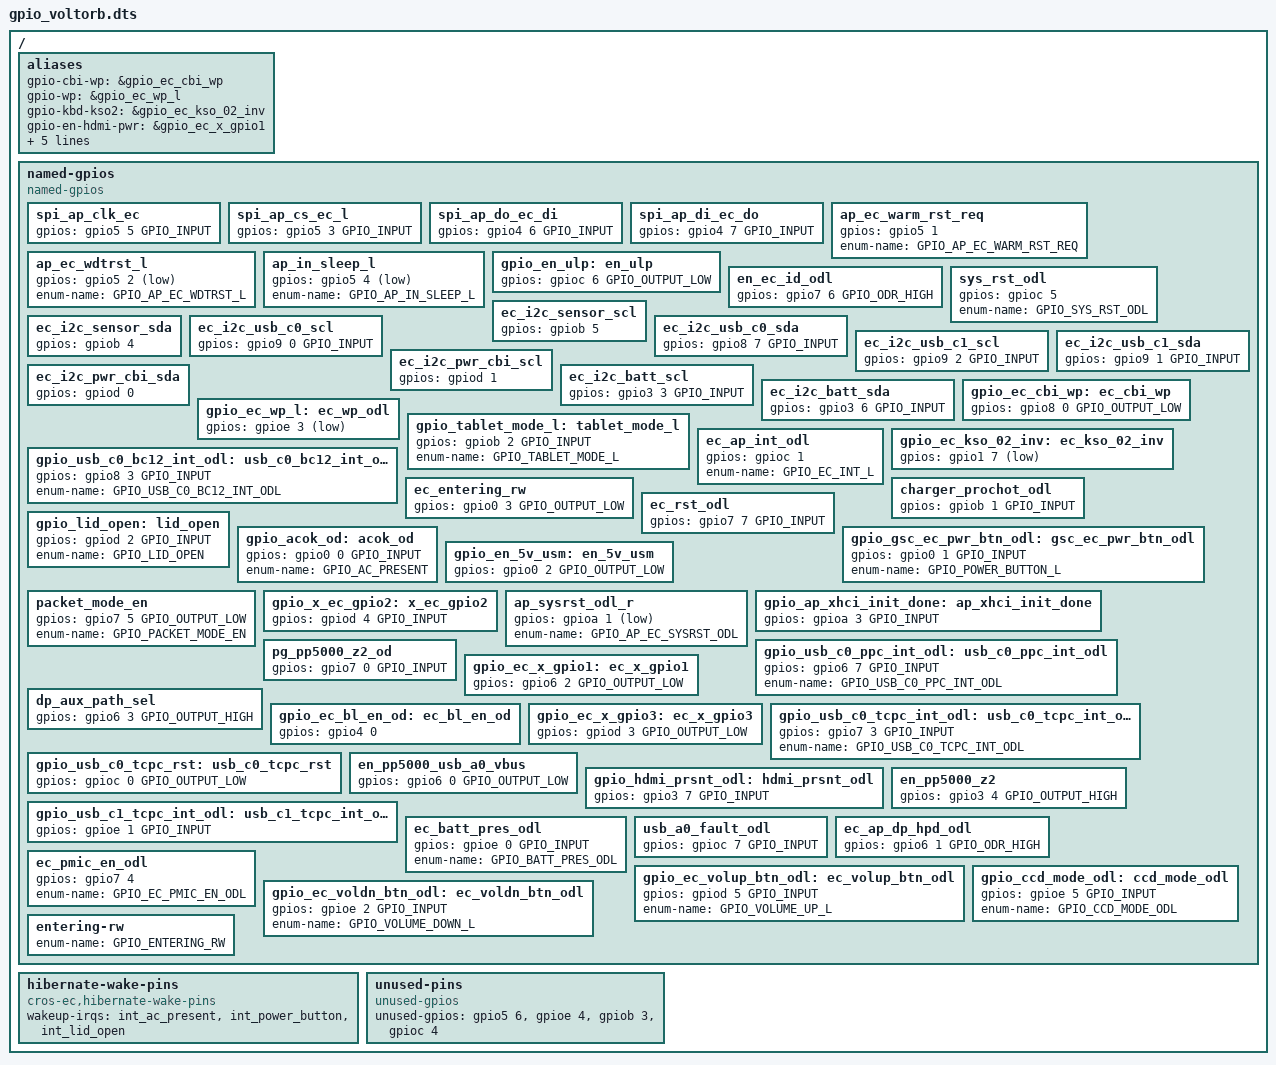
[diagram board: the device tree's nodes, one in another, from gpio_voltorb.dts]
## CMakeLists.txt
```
# Copyright 2021 The ChromiumOS Authors
# Use of this source code is governed by a BSD-style license that can be
# found in the LICENSE file.

cmake_minimum_required(VERSION 3.13.1)

find_package(Zephyr REQUIRED HINTS "${ZEPHYR_BASE}")

cros_ec_library_include_directories(include)

# Include selected EC source from the baseboard
zephyr_library_sources(
	"src/board.c"
	"src/hibernate.c"
)

zephyr_library_sources_ifdef(CONFIG_PLATFORM_EC_USBC "src/usbc.c")
zephyr_library_sources_ifdef(CONFIG_PLATFORM_EC_USBC "src/usb_pd_policy.c")
zephyr_library_sources_ifdef(CONFIG_VARIANT_CORSOLA_DB_DETECTION
			     "src/variant_db_detection.c")
zephyr_library_sources_ifndef(CONFIG_CORSOLA_BOARD_CHIPSET_CUSTOM "src/board_chipset.c")

if(DEFINED CONFIG_BOARD_KRABBY)
	project(krabby)
	add_subdirectory(krabby)
elseif(DEFINED CONFIG_BOARD_KINGLER)
	project(kingler)
	add_subdirectory(kingler)
elseif(DEFINED CONFIG_BOARD_KYOGRE)
	project(kyogre)
	add_subdirectory(kyogre)
elseif(DEFINED CONFIG_BOARD_STARMIE)
	project(starmie)
	add_subdirectory(starmie)
elseif(DEFINED CONFIG_BOARD_STEELIX)
	project(steelix)
	add_subdirectory(steelix)
elseif(DEFINED CONFIG_BOARD_TENTACRUEL)
	project(tentacruel)
	add_subdirectory(tentacruel)
elseif(DEFINED CONFIG_BOARD_MAGIKARP)
	project(magikarp)
	add_subdirectory(magikarp)
elseif(DEFINED CONFIG_BOARD_VOLTORB)
	project(voltorb)
	add_subdirectory(voltorb)
elseif(DEFINED CONFIG_BOARD_PONYTA)
	project(ponyta)
	add_subdirectory(ponyta)
elseif(DEFINED CONFIG_BOARD_CHINCHOU)
	project(chinchou)
	add_subdirectory(chinchou)
elseif(DEFINED CONFIG_BOARD_WUGTRIO)
	project(wugtrio)
	add_subdirectory(wugtrio)
elseif(DEFINED CONFIG_BOARD_SKITTY)
	project(skitty)
	add_subdirectory(skitty)
elseif(DEFINED CONFIG_BOARD_VELUZA)
	project(veluza)
	add_subdirectory(veluza)
elseif(DEFINED CONFIG_BOARD_SQUIRTLE)
	project(squirtle)
	add_subdirectory(squirtle)
elseif(DEFINED CONFIG_BOARD_WYRDEER)
	project(wyrdeer)
	add_subdirectory(wyrdeer)
elseif(DEFINED CONFIG_BOARD_MEWTWO)
    project(mewtwo)
    add_subdirectory(mewtwo)
endif()
```

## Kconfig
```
# Copyright 2021 The ChromiumOS Authors
# Use of this source code is governed by a BSD-style license that can be
# found in the LICENSE file.

config BOARD_KRABBY
	bool "Google Krabby Board"
	help
	  Build Google Krabby reference board. Krabby has MediaTek MT8186 SoC
	  with ITE it81202-bx EC.

config BOARD_KINGLER
	bool "Google Kingler Board"
	help
	  Build Google Kingler reference board. Krabby has MediaTek MT8186 SoC
	  with NPCX993FA0BX EC.

config BOARD_KYOGRE
	bool "Google Kyogre Board"
	help
	  Build Google Kyogre variant board. Kyogre is a variant of Kingler
	  and has MediaTek MT8186 SoC with NPCX993FA0BX EC.

config BOARD_STARMIE
	bool "Google Starmie Board"
	help
	  Build Google Starmie variant board. Starmie is a variant of Krabby
	  and has MediaTek MT8186 SoC with ITE it81202-bx EC

config BOARD_STEELIX
	bool "Google Steelix Board"
	help
	  Build Google Steelix variant board. Steelix is a variant of Kingler
	  and has MediaTek MT8186 SoC with NPCX993FA0BX EC.

config BOARD_TENTACRUEL
	bool "Google Tentacruel Board"
	help
	  Build Google Tentacruel variant board. Tentacruel is a variant of Krabby
	  and has MediaTek MT8186 SoC with ITE it81202-bx EC.

config BOARD_MAGIKARP
	bool "Google Magikarp Board"
	help
	  Build Google Magikarp variant board. Magikarp is a variant of Krabby
	  and has MediaTek MT8186 SoC with ITE it81202-bx EC.

config BOARD_VOLTORB
	bool "Google Voltorb Board"
	help
	  Build Google Voltorb variant board. Voltorb is a variant of Kingler
	  and has MediaTek MT8186/MT8186T SoC with NPCX993FA0BX EC.

config BOARD_PONYTA
	bool "Google Ponyta Board"
	help
	  Build Google Ponyta variant board. Ponyta is a variant of Kingler
	  and has MediaTek MT8186 SoC with NPCX993FA0BX EC.

config BOARD_CHINCHOU
	bool "Google Chinchou Board"
	help
	  Build Google Chinchou variant board. Chinchou is a variant of Krabby
	  and has MediaTek MT8186 SoC with ITE it81202-bx EC

config BOARD_WUGTRIO
	bool "Google Wugtrio Board"
	help
	  Build Google Wugtrio variant board. Wugtrio is a variant of Krabby
	  and has MediaTek MT8186 SoC with ITE it81202-bx EC

config BOARD_SKITTY
	bool "Google Skitty Board"
	help
	  Build Google Skitty variant board. Skitty is a variant of Krabby
	  and has MediaTek MT8186 SoC with ITE it81202-bx EC

config BOARD_VELUZA
	bool "Google Veluza Board"
	help
	  Build Google Veluza variant board. Veluza is a variant of Krabby
	  and has MediaTek MT8186 SoC with ITE it81202-bx EC

config BOARD_SQUIRTLE
	bool "Google Squirtle Board"
	help
	  Build Google Squirtle variant board. Squirtle is a variant of Kingler
	  and has MediaTek MT8186/MT8186T SoC with NPCX993FA0BX EC.

config BOARD_WYRDEER
	bool "Google Wyrdeer Board"
	help
	  Build Google Wyrdeer variant board. Wyrdeer is a variant of Krabby
	  and has MediaTek MT8186 SoC with ITE it81202-bx EC

config BOARD_MEWTWO
        bool "Google Squirtle Board"
        help
          Build Google Squirtle variant board. Squirtle is a variant of Kingler
          and has MediaTek MT8186/MT8186T SoC with NPCX993FA0BX EC.

config VARIANT_CORSOLA_DB_DETECTION
	bool "Corsola Platform Runtime Daughter Board Detection"
	depends on PLATFORM_EC_USB_PD_TCPC_RUNTIME_CONFIG
	depends on PLATFORM_EC_USB_MUX_RUNTIME_CONFIG
	help
	  Daughter board detection for Type-C subboard or HDMI subboard. This
          includes pin configuration and driver loading.
	default y

config CORSOLA_HIBERNATE_PRE_OFF_5V
	bool "Corsola Platform Hibernate Power Sequence Selection"
	help
	  Set PP5000_Z2 to deactivate before executing normal corsola hibernate.
	default n

config CORSOLA_BOARD_CHIPSET_CUSTOM
	bool "Corsola Platform Board Chipset Customization"
	help
	  Enable corsola platform customized AP power callbacks.
	default n

source "Kconfig.zephyr"
```

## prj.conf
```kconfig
# Copyright 2021 The ChromiumOS Authors
# Use of this source code is governed by a BSD-style license that can be
# found in the LICENSE file.
#

# http://google3/hardware/standards/usb/
CONFIG_PLATFORM_EC_USB_PID=0x505C

# CROS EC
CONFIG_CROS_EC=y
CONFIG_PLATFORM_EC=y
CONFIG_PLATFORM_EC_SWITCH=y
CONFIG_SHIMMED_TASKS=y

# AP SoC configuration
CONFIG_AP=y
CONFIG_AP_ARM_MTK_MT8186=y

# Variant config
CONFIG_VARIANT_CORSOLA_DB_DETECTION=y

# Shell features
CONFIG_KERNEL_SHELL=y
CONFIG_SHELL_HELP=y
CONFIG_SHELL_HISTORY=y
CONFIG_SHELL_TAB=y
CONFIG_SHELL_TAB_AUTOCOMPLETION=y

# CBI
CONFIG_EEPROM=y
CONFIG_PLATFORM_EC_BOARD_VERSION_CBI=y

# Keyboard
CONFIG_PLATFORM_EC_KEYBOARD=y
CONFIG_PLATFORM_EC_KEYBOARD_PROTOCOL_MKBP=y
CONFIG_PLATFORM_EC_KEYBOARD_COL2_INVERTED=y

# MKBP
CONFIG_PLATFORM_EC_MKBP_EVENT=y
CONFIG_PLATFORM_EC_MKBP_INPUT_DEVICES=y
CONFIG_PLATFORM_EC_MKBP_USE_GPIO=y

# EFS2
CONFIG_PLATFORM_EC_VBOOT_EFS2=y

# USB
CONFIG_PLATFORM_EC_USB_PD_TBT_COMPAT_MODE=n
CONFIG_PLATFORM_EC_USB_PD_USB32_DRD=n
CONFIG_PLATFORM_EC_USB_PD_USB4=n
CONFIG_PLATFORM_EC_USB_PORT_POWER_DUMB_CUSTOM_HOOK=y

# USB-C
CONFIG_PLATFORM_EC_USBC=y
CONFIG_PLATFORM_EC_USBC_SS_MUX_DFP_ONLY=y
CONFIG_PLATFORM_EC_USB_PD_DPS=y
CONFIG_PLATFORM_EC_USB_PD_DP_HPD_GPIO=y
CONFIG_PLATFORM_EC_USB_PD_DP_HPD_GPIO_CUSTOM=y
CONFIG_PLATFORM_EC_USB_PD_FRS=y
CONFIG_PLATFORM_EC_USB_PD_CLEAR_HARD_RESET_STATUS=y

# Power Seq
CONFIG_PLATFORM_EC_CHIPSET_RESUME_INIT_HOOK=y
CONFIG_PLATFORM_EC_EXTPOWER_GPIO=y
CONFIG_PLATFORM_EC_POWERSEQ=y
CONFIG_PLATFORM_EC_POWERSEQ_HOST_SLEEP=y
CONFIG_PLATFORM_EC_POWERSEQ_PP5000_CONTROL=n
CONFIG_PLATFORM_EC_POWER_SLEEP_FAILURE_DETECTION=y

# Optional features
CONFIG_FLASH_SHELL=n

# EEPROM
CONFIG_PLATFORM_EC_EEPROM_CBI_WP=y

# Host Commands
CONFIG_PLATFORM_EC_HOSTCMD=y

# Battery
CONFIG_PLATFORM_EC_BATTERY_CUT_OFF=y
CONFIG_PLATFORM_EC_BATTERY_FUEL_GAUGE=y
CONFIG_PLATFORM_EC_BATTERY_PRESENT_GPIO=y
CONFIG_PLATFORM_EC_BATTERY_SMART=y
CONFIG_PLATFORM_EC_BATT_FULL_CHIPSET_OFF_INPUT_LIMIT_MV=9000
CONFIG_PLATFORM_EC_I2C_PASSTHRU_RESTRICTED=y
CONFIG_PLATFORM_EC_I2C_VIRTUAL_BATTERY=y

# Charger
CONFIG_PLATFORM_EC_BC12_CLIENT_MODE_ONLY_PI3USB9201=y
CONFIG_PLATFORM_EC_CHARGE_MANAGER=y
# b:257167723: Adapter output current exceeds the spec on heavy-load.
# Preserve a margin in case of charger overdraw.
CONFIG_PLATFORM_EC_CHARGER_INPUT_CURRENT_DERATE_PCT=3

# Button
CONFIG_PLATFORM_EC_CMD_BUTTON=y
CONFIG_PLATFORM_EC_POWER_BUTTON=y
CONFIG_PLATFORM_EC_VOLUME_BUTTONS=y
```

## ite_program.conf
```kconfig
# Copyright 2022 The ChromiumOS Authors
# Use of this source code is governed by a BSD-style license that can be
# found in the LICENSE file.

# Bring up options
#CONFIG_SHELL_HISTORY_BUFFER=256
CONFIG_PLATFORM_EC_SYSTEM_UNLOCKED=y
CONFIG_PLATFORM_EC_BRINGUP=y

# Power Sequencing
CONFIG_PLATFORM_EC_CHIPSET_RESET_HOOK=y

# Lid Switch
CONFIG_PLATFORM_EC_LID_SWITCH=y

# Charger
CONFIG_PLATFORM_EC_CHARGE_RAMP_HW=y
CONFIG_PLATFORM_EC_CHARGER_DISCHARGE_ON_AC=y
CONFIG_PLATFORM_EC_CHARGER_DISCHARGE_ON_AC_CHARGER=y
CONFIG_PLATFORM_EC_CHARGER_MAINTAIN_VBAT=y
CONFIG_PLATFORM_EC_CHARGER_PSYS=y
CONFIG_PLATFORM_EC_CHARGER_PSYS_READ=y
# BOARD_RS2
CONFIG_PLATFORM_EC_CHARGER_SENSE_RESISTOR=10
# BOARD_RS1
CONFIG_PLATFORM_EC_CHARGER_SENSE_RESISTOR_AC=20
CONFIG_PLATFORM_EC_CONSOLE_CMD_CHARGER_DUMP=y

# Host Commands
CONFIG_PLATFORM_EC_CONSOLE_CMD_ACCELS=y
CONFIG_PLATFORM_EC_CONSOLE_CMD_ACCEL_INFO=y
CONFIG_PLATFORM_EC_CONSOLE_CMD_CHARGER_ADC_AMON_BMON=y
CONFIG_PLATFORM_EC_CONSOLE_CMD_SYSINFO=y
CONFIG_PLATFORM_EC_HOST_COMMAND_STATUS=y

# Sensors
CONFIG_PLATFORM_EC_ACCEL_FIFO=y
CONFIG_PLATFORM_EC_GMR_TABLET_MODE=y
CONFIG_PLATFORM_EC_LID_ANGLE=y
CONFIG_PLATFORM_EC_LID_ANGLE_UPDATE=y
CONFIG_PLATFORM_EC_SENSOR_TIGHT_TIMESTAMPS=y
CONFIG_PLATFORM_EC_TABLET_MODE=y
CONFIG_PLATFORM_EC_TABLET_MODE_SWITCH=y
CONFIG_PLATFORM_EC_MAX_SENSOR_FREQ_MILLIHZ=100000

# Sensor Drivers
CONFIG_PLATFORM_EC_ACCEL_LIS2DW12=y
CONFIG_PLATFORM_EC_ACCELGYRO_ICM42607=y
CONFIG_PLATFORM_EC_ACCELGYRO_ICM_COMM_I2C=y

# Tasks
CONFIG_TASK_CHARGER_STACK_SIZE=1440
CONFIG_TASK_CHIPSET_STACK_SIZE=1440
CONFIG_TASK_MOTIONSENSE_STACK_SIZE=1280
CONFIG_TASK_PD_STACK_SIZE=1280

# USB-C
CONFIG_PLATFORM_EC_USBC_PPC_SYV682C=y
CONFIG_PLATFORM_EC_USB_PD_DISCHARGE_PPC=y
CONFIG_PLATFORM_EC_USB_PD_FRS_PPC=y
CONFIG_PLATFORM_EC_USB_PD_LOGGING=y
CONFIG_PLATFORM_EC_USB_PD_VBUS_DETECT_PPC=y
CONFIG_PLATFORM_EC_USB_PD_VBUS_MEASURE_ADC_EACH_PORT=y
CONFIG_PLATFORM_EC_USB_PD_DUAL_ROLE_AUTO_TOGGLE=n
CONFIG_PLATFORM_EC_USB_PD_3A_PORTS=0
CONFIG_PLATFORM_EC_USB_PD_PULLUP=1

# TODO(b/180980668): bring these features up
CONFIG_PLATFORM_EC_BACKLIGHT_LID=n
```

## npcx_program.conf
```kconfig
# Copyright 2022 The ChromiumOS Authors
# Use of this source code is governed by a BSD-style license that can be
# found in the LICENSE file.


# Bring up options
CONFIG_PLATFORM_EC_SYSTEM_UNLOCKED=y

# Debug options and features; can be disabled to save memory or once bringup
# is complete.
CONFIG_SHELL_MINIMAL=n

# Charger
CONFIG_PLATFORM_EC_CHARGER_DISCHARGE_ON_AC=y
CONFIG_PLATFORM_EC_CHARGER_ISL9238C=y
CONFIG_PLATFORM_EC_CHARGER_PSYS=y
CONFIG_PLATFORM_EC_CHARGER_PSYS_READ=y
CONFIG_PLATFORM_EC_CHARGER_SENSE_RESISTOR=10
CONFIG_PLATFORM_EC_CHARGER_SENSE_RESISTOR_AC=20
CONFIG_PLATFORM_EC_CONSOLE_CMD_CHARGER_ADC_AMON_BMON=y

# PWM
CONFIG_PWM=y

# LED
CONFIG_PLATFORM_EC_LED_COMMON=y
CONFIG_PLATFORM_EC_LED_ONOFF_STATES=y

# Math
CONFIG_PLATFORM_EC_MATH_UTIL=y

# Power sequencing
CONFIG_PLATFORM_EC_POWERSEQ_MT8186=y
CONFIG_PLATFORM_EC_POWERSEQ_S4=n

# Button
CONFIG_PLATFORM_EC_BUTTONS_RUNTIME_CONFIG=y

# Sensors
CONFIG_PLATFORM_EC_ACCELGYRO_BMI3XX=y
CONFIG_PLATFORM_EC_ACCELGYRO_BMI_COMM_I2C=y
CONFIG_PLATFORM_EC_ACCEL_BMA4XX=y
CONFIG_PLATFORM_EC_ACCEL_FIFO=y
CONFIG_PLATFORM_EC_CONSOLE_CMD_ACCELS=y
CONFIG_PLATFORM_EC_CONSOLE_CMD_ACCEL_INFO=y
CONFIG_PLATFORM_EC_GMR_TABLET_MODE=y
CONFIG_PLATFORM_EC_LID_ANGLE=y
CONFIG_PLATFORM_EC_LID_ANGLE_UPDATE=y
CONFIG_PLATFORM_EC_LID_SWITCH=y
CONFIG_PLATFORM_EC_SENSOR_TIGHT_TIMESTAMPS=y
CONFIG_PLATFORM_EC_TABLET_MODE=y
CONFIG_PLATFORM_EC_TABLET_MODE_SWITCH=y

# USBC
CONFIG_PLATFORM_EC_PD_POWER_SUPPLY_TURN_OFF_DELAY=15000
CONFIG_PLATFORM_EC_PD_POWER_SUPPLY_TURN_ON_DELAY=15000
CONFIG_PLATFORM_EC_USBC_PPC=y
CONFIG_PLATFORM_EC_USB_PD_DISCHARGE_PPC=y
CONFIG_PLATFORM_EC_USB_PD_FRS_TCPC=y
CONFIG_PLATFORM_EC_USB_PD_LOGGING=y
CONFIG_PLATFORM_EC_USB_PD_DEBUG_FIXED_LEVEL=y
CONFIG_PLATFORM_EC_USB_PD_DEBUG_LEVEL=2
CONFIG_PLATFORM_EC_USB_PD_TCPM_ANX7447_AUX_PU_PD=y
CONFIG_PLATFORM_EC_USB_PD_TCPM_SBU=y
CONFIG_PLATFORM_EC_USB_PD_VBUS_DETECT_TCPC=y
CONFIG_PLATFORM_EC_USB_PD_VBUS_MEASURE_BY_BOARD=y

# External power
CONFIG_PLATFORM_EC_BACKLIGHT_LID=n

# Keyboard
CONFIG_CROS_KB_RAW_NPCX_KSO_HIGH_DRIVE=y

CONFIG_SYSCON=y

CONFIG_PLATFORM_EC_BOARD_VERSION_GPIO=n
```

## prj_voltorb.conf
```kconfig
# Copyright 2022 The ChromiumOS Authors
# Use of this source code is governed by a BSD-style license that can be
# found in the LICENSE file.

# Variant config
CONFIG_BOARD_VOLTORB=y

# Voltorb only use D2, drop the workaround config for H1
CONFIG_PLATFORM_EC_BOARD_RESET_AFTER_POWER_ON=n

# No A+Gsensor
CONFIG_PLATFORM_EC_ACCELGYRO_BMI_COMM_I2C=n
CONFIG_PLATFORM_EC_ACCELGYRO_BMI3XX=n
CONFIG_PLATFORM_EC_ACCEL_BMA4XX=n
CONFIG_PLATFORM_EC_ACCEL_FIFO=n
CONFIG_PLATFORM_EC_CONSOLE_CMD_ACCELS=n
CONFIG_PLATFORM_EC_CONSOLE_CMD_ACCEL_INFO=n
CONFIG_PLATFORM_EC_GMR_TABLET_MODE=n
CONFIG_PLATFORM_EC_LID_ANGLE=n
CONFIG_PLATFORM_EC_LID_ANGLE_UPDATE=n
CONFIG_PLATFORM_EC_LID_SWITCH=y
CONFIG_PLATFORM_EC_MOTIONSENSE=n
CONFIG_PLATFORM_EC_SENSOR_TIGHT_TIMESTAMPS=n
CONFIG_PLATFORM_EC_TABLET_MODE=n
CONFIG_PLATFORM_EC_TABLET_MODE_SWITCH=n

# LED
CONFIG_PLATFORM_EC_LED_COMMON=n
CONFIG_PLATFORM_EC_LED_ONOFF_STATES=n
CONFIG_PLATFORM_EC_LED_DT=y

# Keyboard
CONFIG_PLATFORM_EC_KEYBOARD_REFRESH_ROW3=y
CONFIG_PLATFORM_EC_KEYBOARD_PWRBTN_ASSERTS_KSI3=y
CONFIG_PLATFORM_EC_KEYBOARD_STRICT_DEBOUNCE=y

# USBC
CONFIG_PLATFORM_EC_PD_MAX_CURRENT_MA=3250
CONFIG_PLATFORM_EC_PD_MAX_POWER_MW=65000

# Remove bring up options for FW QUAL

# Remove debug options and features for FW QUAL
CONFIG_SHELL_MINIMAL=y

# AC_OK debounce time
CONFIG_PLATFORM_EC_EXTPOWER_DEBOUNCE_MS=800
```

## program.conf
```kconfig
# Copyright 2021 The ChromiumOS Authors
# Use of this source code is governed by a BSD-style license that can be
# found in the LICENSE file.
#

# http://google3/hardware/standards/usb/
CONFIG_PLATFORM_EC_USB_PID=0x505C

# CROS EC
CONFIG_CROS_EC=y
CONFIG_PLATFORM_EC=y
CONFIG_PLATFORM_EC_SWITCH=y

# AP SoC configuration
CONFIG_AP=y
CONFIG_AP_ARM_MTK_MT8186=y

# Variant config
CONFIG_VARIANT_CORSOLA_DB_DETECTION=y

# Shell features
CONFIG_KERNEL_SHELL=y
CONFIG_SHELL_HELP=y
CONFIG_SHELL_HISTORY=y
CONFIG_SHELL_TAB=y
CONFIG_SHELL_TAB_AUTOCOMPLETION=y
CONFIG_I2C_SHELL=y

# CBI
CONFIG_EEPROM=y
CONFIG_PLATFORM_EC_BOARD_VERSION_CBI=y

# Keyboard
CONFIG_PLATFORM_EC_KEYBOARD_PROTOCOL_MKBP=y
CONFIG_PLATFORM_EC_KEYBOARD_COL2_INVERTED=y

# MKBP
CONFIG_PLATFORM_EC_MKBP_EVENT=y
CONFIG_PLATFORM_EC_MKBP_INPUT_DEVICES=y
CONFIG_PLATFORM_EC_MKBP_USE_GPIO=y

# EFS2
CONFIG_PLATFORM_EC_VBOOT_EFS2=y

# USB
CONFIG_PLATFORM_EC_USB_PD_TBT_COMPAT_MODE=n
CONFIG_PLATFORM_EC_USB_PD_USB32_DRD=n
CONFIG_PLATFORM_EC_USB_PD_USB4=n
CONFIG_PLATFORM_EC_USB_PORT_POWER_DUMB_CUSTOM_HOOK=y

# USB-C
CONFIG_PLATFORM_EC_USBC=y
CONFIG_PLATFORM_EC_USBC_SS_MUX_DFP_ONLY=y
CONFIG_PLATFORM_EC_USB_PD_DPS=y
CONFIG_PLATFORM_EC_USB_PD_DP_HPD_GPIO=y
CONFIG_PLATFORM_EC_USB_PD_DP_HPD_GPIO_CUSTOM=y
CONFIG_PLATFORM_EC_USB_PD_FRS=y
CONFIG_PLATFORM_EC_USB_PD_CLEAR_HARD_RESET_STATUS=y

# Power Seq
CONFIG_PLATFORM_EC_CHIPSET_RESUME_INIT_HOOK=y
CONFIG_PLATFORM_EC_EXTPOWER_GPIO=y
CONFIG_PLATFORM_EC_POWERSEQ=y
CONFIG_PLATFORM_EC_POWERSEQ_HOST_SLEEP=y
CONFIG_PLATFORM_EC_POWERSEQ_PP5000_CONTROL=n
CONFIG_PLATFORM_EC_POWER_SLEEP_FAILURE_DETECTION=y

# EEPROM
CONFIG_PLATFORM_EC_EEPROM_CBI_WP=y

# Host Commands
CONFIG_PLATFORM_EC_HOSTCMD=y

# Battery
CONFIG_PLATFORM_EC_BATTERY_CUT_OFF=y
CONFIG_PLATFORM_EC_BATTERY_FUEL_GAUGE=y
CONFIG_PLATFORM_EC_BATT_FULL_CHIPSET_OFF_INPUT_LIMIT_MV=9000
CONFIG_PLATFORM_EC_I2C_PASSTHRU_RESTRICTED=y
CONFIG_PLATFORM_EC_I2C_VIRTUAL_BATTERY=y

# Charger
CONFIG_PLATFORM_EC_BC12_CLIENT_MODE_ONLY_PI3USB9201=y
CONFIG_PLATFORM_EC_CHARGE_MANAGER=y
# b:257167723: Adapter output current exceeds the spec on heavy-load.
# Preserve a margin in case of charger overdraw.
CONFIG_PLATFORM_EC_CHARGER_INPUT_CURRENT_DERATE_PCT=3

# Button
CONFIG_PLATFORM_EC_CMD_BUTTON=y
CONFIG_PLATFORM_EC_POWER_BUTTON=y
CONFIG_PLATFORM_EC_VOLUME_BUTTONS=y

# Kernel debugging
CONFIG_PLATFORM_EC_EMULATED_SYSRQ=y

CONFIG_PLATFORM_EC_USB_PD_INITIAL_DEBUG_LEVEL=0

# Upstream Zephyr Host Command
CONFIG_EC_HOST_CMD=y
```

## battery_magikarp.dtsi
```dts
/* Copyright 2022 The ChromiumOS Authors
 * Use of this source code is governed by a BSD-style license that can be
 * found in the LICENSE file.
 */

/ {
};
```

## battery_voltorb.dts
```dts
/* Copyright 2021 The ChromiumOS Authors
 * Use of this source code is governed by a BSD-style license that can be
 * found in the LICENSE file.
 */

/ {
	batteries {
		default_battery: cosmx_ap20cbl-2 {
			compatible = "cosmx,ap20cbl-2", "battery-smart";
		};
		lgc_ap18c8k {
			compatible = "lgc,ap18c8k", "battery-smart";
		};
		lgc_ap19b8k {
			compatible = "lgc,ap19b8k", "battery-smart";
		};
		panasonic_ap19b5k {
			compatible = "panasonic,ap19b5k", "battery-smart";
		};
	};
};
```

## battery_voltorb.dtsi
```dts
/* Copyright 2022 The ChromiumOS Authors
 * Use of this source code is governed by a BSD-style license that can be
 * found in the LICENSE file.
 */

/ {
	batteries {
		default_battery: cosmx_ap20cbl-2 {
			compatible = "cosmx,ap20cbl-2", "battery-smart";
		};
		lgc_ap18c8k {
			compatible = "lgc,ap18c8k", "battery-smart";
		};
		lgc_ap19b8k {
			compatible = "lgc,ap19b8k", "battery-smart";
		};
		panasonic_ap19b5k {
			compatible = "panasonic,ap19b5k", "battery-smart";
		};
	};
};
```

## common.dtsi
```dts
/* Copyright 2022 The ChromiumOS Authors
 * Use of this source code is governed by a BSD-style license that can be
 * found in the LICENSE file.
 */

#include <dt-bindings/wake_mask_event_defines.h>

/ {
	ec-mkbp-host-event-wakeup-mask {
		compatible = "cros-ec,mkbp-host-event-wakeup-mask";
		wakeup-mask = <(
			HOST_EVENT_AC_CONNECTED |
			HOST_EVENT_AC_DISCONNECTED |
			HOST_EVENT_LID_CLOSED |
			HOST_EVENT_LID_OPEN |
			HOST_EVENT_POWER_BUTTON |
			HOST_EVENT_HANG_DETECT |
			HOST_EVENT_MODE_CHANGE)>;
	};

	ec-mkbp-event-wakeup-mask {
		compatible = "cros-ec,mkbp-event-wakeup-mask";
		wakeup-mask = <(MKBP_EVENT_KEY_MATRIX |
				MKBP_EVENT_HOST_EVENT)>;
	};
};
```

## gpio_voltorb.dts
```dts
/* Copyright 2021 The ChromiumOS Authors
 * Use of this source code is governed by a BSD-style license that can be
 * found in the LICENSE file.
 */

/ {
	aliases {
		gpio-cbi-wp = &gpio_ec_cbi_wp;
		gpio-wp = &gpio_ec_wp_l;
		gpio-kbd-kso2 = &gpio_ec_kso_02_inv;
	};

	named-gpios {
		compatible = "named-gpios";

		/*
		 * In npcx9 series, gpio46, gpio47, and the whole gpio5 port
		 * belong to VHIF power well. On Voltorb, it is connencted to
		 * 1.8V.
		 */
		spi_ap_clk_ec {
			gpios = <&gpio5 5 GPIO_INPUT>;
		};
		spi_ap_cs_ec_l {
			gpios = <&gpio5 3 GPIO_INPUT>;
		};
		spi_ap_do_ec_di {
			gpios = <&gpio4 6 GPIO_INPUT>;
		};
		spi_ap_di_ec_do {
			gpios = <&gpio4 7 GPIO_INPUT>;
		};
		ap_ec_warm_rst_req: ap_ec_warm_rst_req {
			gpios = <&gpio5 1 (GPIO_INPUT | GPIO_ACTIVE_HIGH)>;
			enum-name = "GPIO_AP_EC_WARM_RST_REQ";
		};
		ap_ec_wdtrst_l: ap_ec_wdtrst_l {
			gpios = <&gpio5 2 (GPIO_INPUT | GPIO_ACTIVE_LOW)>;
			enum-name = "GPIO_AP_EC_WDTRST_L";
		};
		ap_in_sleep_l: ap_in_sleep_l {
			gpios = <&gpio5 4 (GPIO_INPUT | GPIO_ACTIVE_LOW)>;
			enum-name = "GPIO_AP_IN_SLEEP_L";
		};
		gpio_en_ulp: en_ulp {
			gpios = <&gpioc 6 GPIO_OUTPUT_LOW>;
		};
		en_ec_id_odl {
			gpios = <&gpio7 6 GPIO_ODR_HIGH>;
		};
		sys_rst_odl {
			gpios = <&gpioc 5 (GPIO_ODR_LOW | GPIO_VOLTAGE_1P8)>;
			enum-name = "GPIO_SYS_RST_ODL";
		};
		ec_i2c_sensor_scl {
			gpios = <&gpiob 5 (GPIO_INPUT | GPIO_VOLTAGE_1P8)>;
		};
		ec_i2c_sensor_sda {
			gpios = <&gpiob 4 (GPIO_INPUT | GPIO_VOLTAGE_1P8)>;
		};
		ec_i2c_usb_c0_scl {
			gpios = <&gpio9 0 GPIO_INPUT>;
		};
		ec_i2c_usb_c0_sda {
			gpios = <&gpio8 7 GPIO_INPUT>;
		};
		ec_i2c_usb_c1_scl {
			gpios = <&gpio9 2 GPIO_INPUT>;
		};
		ec_i2c_usb_c1_sda {
			gpios = <&gpio9 1 GPIO_INPUT>;
		};
		ec_i2c_pwr_cbi_scl {
			gpios = <&gpiod 1 (GPIO_INPUT | GPIO_VOLTAGE_1P8)>;
		};
		ec_i2c_pwr_cbi_sda {
			gpios = <&gpiod 0 (GPIO_INPUT | GPIO_VOLTAGE_1P8)>;
		};
		ec_i2c_batt_scl {
			gpios = <&gpio3 3 GPIO_INPUT>;
		};
		ec_i2c_batt_sda {
			gpios = <&gpio3 6 GPIO_INPUT>;
		};
		gpio_ec_cbi_wp: ec_cbi_wp {
			gpios = <&gpio8 0 GPIO_OUTPUT_LOW>;
		};
		gpio_ec_wp_l: ec_wp_odl {
			gpios = <&gpioe 3 (GPIO_INPUT | GPIO_ACTIVE_LOW |
				 GPIO_VOLTAGE_1P8)>;
		};
		gpio_tablet_mode_l: tablet_mode_l {
			gpios = <&gpiob 2 GPIO_INPUT>;
			enum-name = "GPIO_TABLET_MODE_L";
		};
		ec_ap_int_odl {
			gpios = <&gpioc 1 (GPIO_ODR_HIGH | GPIO_VOLTAGE_1P8)>;
			enum-name = "GPIO_EC_INT_L";
		};
		gpio_ec_kso_02_inv: ec_kso_02_inv {
			gpios = <&gpio1 7 (GPIO_OUTPUT_LOW | GPIO_ACTIVE_LOW)>;
		};
		gpio_usb_c0_bc12_int_odl: usb_c0_bc12_int_odl {
			gpios = <&gpio8 3 GPIO_INPUT>;
			enum-name = "GPIO_USB_C0_BC12_INT_ODL";
		};
		ec_entering_rw {
			gpios = <&gpio0 3 GPIO_OUTPUT_LOW>;
		};
		charger_prochot_odl {
			gpios = <&gpiob 1 GPIO_INPUT>;
		};
		ec_rst_odl {
			gpios = <&gpio7 7 GPIO_INPUT>;
		};
		gpio_lid_open: lid_open {
			gpios = <&gpiod 2 GPIO_INPUT>;
			enum-name = "GPIO_LID_OPEN";
		};
		gpio_acok_od: acok_od {
			gpios = <&gpio0 0 GPIO_INPUT>;
			enum-name = "GPIO_AC_PRESENT";
		};
		gpio_gsc_ec_pwr_btn_odl: gsc_ec_pwr_btn_odl {
			gpios = <&gpio0 1 GPIO_INPUT>;
			enum-name = "GPIO_POWER_BUTTON_L";
		};
		gpio_en_5v_usm: en_5v_usm {
			gpios = <&gpio0 2 GPIO_OUTPUT_LOW>;
		};
		packet_mode_en {
			gpios = <&gpio7 5 GPIO_OUTPUT_LOW>;
			enum-name = "GPIO_PACKET_MODE_EN";
		};
		gpio_x_ec_gpio2: x_ec_gpio2 {
			gpios = <&gpiod 4 GPIO_INPUT>;
		};
		/*
		 * In npcx9 series, gpio93-97, the whole gpioa port, and gpiob0
		 * belong to VSPI power well. On Voltorb, it is connencted to
		 * 1.8V.
		 */
		ap_sysrst_odl_r: ap_sysrst_odl_r {
			gpios = <&gpioa 1 (GPIO_INPUT | GPIO_ACTIVE_LOW)>;
			enum-name = "GPIO_AP_EC_SYSRST_ODL";
		};
		gpio_ap_xhci_init_done: ap_xhci_init_done {
			gpios = <&gpioa 3 GPIO_INPUT>;
		};
		gpio_usb_c0_ppc_int_odl: usb_c0_ppc_int_odl {
			gpios = <&gpio6 7 GPIO_INPUT>;
			enum-name = "GPIO_USB_C0_PPC_INT_ODL";
		};
		pg_pp5000_z2_od {
			gpios = <&gpio7 0 GPIO_INPUT>;
		};
		gpio_ec_x_gpio1: ec_x_gpio1 {
			gpios = <&gpio6 2 GPIO_OUTPUT_LOW>;
		};
		dp_aux_path_sel: dp_aux_path_sel {
			gpios = <&gpio6 3 GPIO_OUTPUT_HIGH>;
		};
		gpio_ec_bl_en_od: ec_bl_en_od {
			gpios = <&gpio4 0 (GPIO_ODR_LOW | GPIO_VOLTAGE_1P8)>;
		};
		gpio_ec_x_gpio3: ec_x_gpio3 {
			gpios = <&gpiod 3 GPIO_OUTPUT_LOW>;
		};
		gpio_usb_c0_tcpc_int_odl: usb_c0_tcpc_int_odl {
			gpios = <&gpio7 3 GPIO_INPUT>;
			enum-name = "GPIO_USB_C0_TCPC_INT_ODL";
		};
		gpio_usb_c0_tcpc_rst: usb_c0_tcpc_rst {
			gpios = <&gpioc 0 GPIO_OUTPUT_LOW>;
		};
		en_pp5000_usb_a0_vbus: en_pp5000_usb_a0_vbus {
			gpios = <&gpio6 0 GPIO_OUTPUT_LOW>;
		};
		gpio_hdmi_prsnt_odl: hdmi_prsnt_odl {
			gpios = <&gpio3 7 GPIO_INPUT>;
		};
		en_pp5000_z2 {
			gpios = <&gpio3 4 GPIO_OUTPUT_HIGH>;
		};
		gpio_usb_c1_tcpc_int_odl: usb_c1_tcpc_int_odl {
			gpios = <&gpioe 1 GPIO_INPUT>;
		};
		ec_batt_pres_odl {
			gpios = <&gpioe 0 GPIO_INPUT>;
			enum-name = "GPIO_BATT_PRES_ODL";
		};
		usb_a0_fault_odl {
			gpios = <&gpioc 7 GPIO_INPUT>;
		};
		ec_ap_dp_hpd_odl: ec_ap_dp_hpd_odl {
			gpios = <&gpio6 1 GPIO_ODR_HIGH>;
		};
		ec_pmic_en_odl {
			gpios = <&gpio7 4 (GPIO_ODR_HIGH | GPIO_VOLTAGE_1P8)>;
			enum-name = "GPIO_EC_PMIC_EN_ODL";
		};
		gpio_ec_volup_btn_odl: ec_volup_btn_odl {
			gpios = <&gpiod 5 GPIO_INPUT>;
			enum-name = "GPIO_VOLUME_UP_L";
		};
		gpio_ec_voldn_btn_odl: ec_voldn_btn_odl {
			gpios = <&gpioe 2 GPIO_INPUT>;
			enum-name = "GPIO_VOLUME_DOWN_L";
		};
		gpio_ccd_mode_odl: ccd_mode_odl {
			gpios = <&gpioe 5 GPIO_INPUT>;
			enum-name = "GPIO_CCD_MODE_ODL";
		};

		/* unimplemented GPIOs */
		entering-rw {
			enum-name = "GPIO_ENTERING_RW";
		};
	};

	/*
	 * aliases for sub-board GPIOs
	 */
	aliases {
		gpio-en-hdmi-pwr = &gpio_ec_x_gpio1;
		gpio-usb-c1-frs-en = &gpio_ec_x_gpio1;
		gpio-usb-c1-ppc-int-odl = &gpio_x_ec_gpio2;
		gpio-ps185-ec-dp-hpd = &gpio_x_ec_gpio2;
		gpio-usb-c1-dp-in-hpd = &gpio_ec_x_gpio3;
		gpio-ps185-pwrdn-odl = &gpio_ec_x_gpio3;
	};

	hibernate-wake-pins {
		compatible = "cros-ec,hibernate-wake-pins";
		wakeup-irqs = <
			&int_ac_present
			&int_power_button
			&int_lid_open
		>;
	};

	unused-pins {
		compatible = "unused-gpios";
		unused-gpios =
			/* base_imu_int_l: base_imu_int_l */
			<&gpio5 6 0>,
			/* ec_pen_chg_dis_odl */
			<&gpioe 4 0>,
			/* lid_accel_int_l */
			<&gpiob 3 0>,
			/* LED3 */
			<&gpioc 4 0>;
	};
};
```

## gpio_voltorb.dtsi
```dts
/* Copyright 2022 The ChromiumOS Authors
 * Use of this source code is governed by a BSD-style license that can be
 * found in the LICENSE file.
 */

#include <dt-bindings/gpio_defines.h>

/ {
	aliases {
		gpio-cbi-wp = &gpio_ec_cbi_wp;
		gpio-wp = &gpio_ec_wp_l;
		gpio-kbd-kso2 = &gpio_ec_kso_02_inv;
	};

	named-gpios {
		compatible = "named-gpios";

		/*
		 * In npcx9 series, gpio46, gpio47, and the whole gpio5 port
		 * belong to VHIF power well. On Voltorb, it is connencted to
		 * 1.8V.
		 */
		spi_ap_clk_ec {
			gpios = <&gpio5 5 GPIO_INPUT>;
		};
		spi_ap_cs_ec_l {
			gpios = <&gpio5 3 GPIO_INPUT>;
		};
		spi_ap_do_ec_di {
			gpios = <&gpio4 6 GPIO_INPUT>;
		};
		spi_ap_di_ec_do {
			gpios = <&gpio4 7 GPIO_INPUT>;
		};
		ap_ec_warm_rst_req: ap_ec_warm_rst_req {
			gpios = <&gpio5 1 (GPIO_INPUT | GPIO_ACTIVE_HIGH)>;
			enum-name = "GPIO_AP_EC_WARM_RST_REQ";
		};
		ap_ec_wdtrst_l: ap_ec_wdtrst_l {
			gpios = <&gpio5 2 (GPIO_INPUT | GPIO_ACTIVE_LOW)>;
			enum-name = "GPIO_AP_EC_WDTRST_L";
		};
		ap_in_sleep_l: ap_in_sleep_l {
			gpios = <&gpio5 4 (GPIO_INPUT | GPIO_ACTIVE_LOW)>;
			enum-name = "GPIO_AP_IN_SLEEP_L";
		};
		gpio_en_ulp: en_ulp {
			gpios = <&gpioc 6 GPIO_OUTPUT_LOW>;
		};
		en_ec_id_odl {
			gpios = <&gpio7 6 GPIO_ODR_HIGH>;
		};
		sys_rst_odl {
			gpios = <&gpioc 5 (GPIO_ODR_LOW | GPIO_VOLTAGE_1P8)>;
			enum-name = "GPIO_SYS_RST_ODL";
		};
		ec_i2c_sensor_scl {
			gpios = <&gpiob 5 (GPIO_INPUT | GPIO_VOLTAGE_1P8)>;
		};
		ec_i2c_sensor_sda {
			gpios = <&gpiob 4 (GPIO_INPUT | GPIO_VOLTAGE_1P8)>;
		};
		ec_i2c_usb_c0_scl {
			gpios = <&gpio9 0 GPIO_INPUT>;
		};
		ec_i2c_usb_c0_sda {
			gpios = <&gpio8 7 GPIO_INPUT>;
		};
		ec_i2c_usb_c1_scl {
			gpios = <&gpio9 2 GPIO_INPUT>;
		};
		ec_i2c_usb_c1_sda {
			gpios = <&gpio9 1 GPIO_INPUT>;
		};
		ec_i2c_pwr_cbi_scl {
			gpios = <&gpiod 1 (GPIO_INPUT | GPIO_VOLTAGE_1P8)>;
		};
		ec_i2c_pwr_cbi_sda {
			gpios = <&gpiod 0 (GPIO_INPUT | GPIO_VOLTAGE_1P8)>;
		};
		ec_i2c_batt_scl {
			gpios = <&gpio3 3 GPIO_INPUT>;
		};
		ec_i2c_batt_sda {
			gpios = <&gpio3 6 GPIO_INPUT>;
		};
		gpio_ec_cbi_wp: ec_cbi_wp {
			gpios = <&gpio8 0 GPIO_OUTPUT_LOW>;
		};
		gpio_ec_wp_l: ec_wp_odl {
			gpios = <&gpioe 3 (GPIO_INPUT | GPIO_ACTIVE_LOW |
				 GPIO_VOLTAGE_1P8)>;
		};
		ec_ap_int_odl {
			gpios = <&gpioc 1 (GPIO_ODR_HIGH | GPIO_VOLTAGE_1P8)>;
			enum-name = "GPIO_EC_INT_L";
		};
		gpio_ec_kso_02_inv: ec_kso_02_inv {
			gpios = <&gpio1 7 (GPIO_OUTPUT_LOW | GPIO_ACTIVE_LOW)>;
		};
		gpio_usb_c0_bc12_int_odl: usb_c0_bc12_int_odl {
			gpios = <&gpio8 3 GPIO_INPUT>;
			enum-name = "GPIO_USB_C0_BC12_INT_ODL";
		};
		ec_entering_rw {
			gpios = <&gpio0 3 GPIO_OUTPUT_LOW>;
		};
		charger_prochot_odl {
			gpios = <&gpiob 1 GPIO_INPUT>;
		};
		ec_rst_odl {
			gpios = <&gpio7 7 GPIO_INPUT>;
		};
		gpio_lid_open: lid_open {
			gpios = <&gpiod 2 GPIO_INPUT>;
			enum-name = "GPIO_LID_OPEN";
		};
		gpio_acok_od: acok_od {
			gpios = <&gpio0 0 GPIO_INPUT>;
			enum-name = "GPIO_AC_PRESENT";
		};
		gpio_gsc_ec_pwr_btn_odl: gsc_ec_pwr_btn_odl {
			gpios = <&gpio0 1 GPIO_INPUT>;
			enum-name = "GPIO_POWER_BUTTON_L";
		};
		gpio_en_5v_usm: en_5v_usm {
			gpios = <&gpio0 2 GPIO_OUTPUT_LOW>;
		};
		packet_mode_en {
			gpios = <&gpio7 5 GPIO_OUTPUT_LOW>;
			enum-name = "GPIO_PACKET_MODE_EN";
		};
		gpio_x_ec_gpio2: x_ec_gpio2 {
			gpios = <&gpiod 4 GPIO_INPUT>;
		};
		/*
		 * In npcx9 series, gpio93-97, the whole gpioa port, and gpiob0
		 * belong to VSPI power well. On Voltorb, it is connencted to
		 * 1.8V.
		 */
		ap_sysrst_odl_r: ap_sysrst_odl_r {
			gpios = <&gpioa 1 (GPIO_INPUT | GPIO_ACTIVE_LOW)>;
			enum-name = "GPIO_AP_EC_SYSRST_ODL";
		};
		gpio_ap_xhci_init_done: ap_xhci_init_done {
			gpios = <&gpioa 3 GPIO_INPUT>;
		};
		gpio_usb_c0_ppc_int_odl: usb_c0_ppc_int_odl {
			gpios = <&gpio6 7 GPIO_INPUT>;
			enum-name = "GPIO_USB_C0_PPC_INT_ODL";
		};
		pg_pp5000_z2_od {
			gpios = <&gpio7 0 GPIO_INPUT>;
		};
		gpio_ec_x_gpio1: ec_x_gpio1 {
			gpios = <&gpio6 2 GPIO_OUTPUT_LOW>;
		};
		dp_aux_path_sel: dp_aux_path_sel {
			gpios = <&gpio6 3 GPIO_OUTPUT_HIGH>;
		};
		gpio_ec_bl_en_od: ec_bl_en_od {
			gpios = <&gpio4 0 (GPIO_ODR_LOW | GPIO_VOLTAGE_1P8)>;
		};
		gpio_ec_x_gpio3: ec_x_gpio3 {
			gpios = <&gpiod 3 GPIO_OUTPUT_LOW>;
		};
		gpio_usb_c0_tcpc_int_odl: usb_c0_tcpc_int_odl {
			gpios = <&gpio7 3 GPIO_INPUT>;
			enum-name = "GPIO_USB_C0_TCPC_INT_ODL";
		};
		gpio_usb_c0_tcpc_rst: usb_c0_tcpc_rst {
			gpios = <&gpioc 0 GPIO_OUTPUT_LOW>;
		};
		en_pp5000_usb_a0_vbus: en_pp5000_usb_a0_vbus {
			gpios = <&gpio6 0 GPIO_OUTPUT_LOW>;
		};
		gpio_hdmi_prsnt_odl: hdmi_prsnt_odl {
			gpios = <&gpio3 7 GPIO_INPUT>;
		};
		en_pp5000_z2 {
			gpios = <&gpio3 4 GPIO_OUTPUT_HIGH>;
		};
		gpio_usb_c1_tcpc_int_odl: usb_c1_tcpc_int_odl {
			gpios = <&gpioe 1 GPIO_INPUT>;
		};
		ec_batt_pres_odl {
			gpios = <&gpioe 0 GPIO_INPUT>;
			enum-name = "GPIO_BATT_PRES_ODL";
		};
		usb_a0_fault_odl {
			gpios = <&gpioc 7 GPIO_INPUT>;
		};
		ec_ap_dp_hpd_odl: ec_ap_dp_hpd_odl {
			gpios = <&gpio6 1 GPIO_ODR_HIGH>;
		};
		ec_pmic_en_odl {
			gpios = <&gpio7 4 (GPIO_ODR_HIGH | GPIO_VOLTAGE_1P8)>;
			enum-name = "GPIO_EC_PMIC_EN_ODL";
		};
		gpio_ec_volup_btn_odl: ec_volup_btn_odl {
			gpios = <&gpiod 5 GPIO_INPUT>;
			enum-name = "GPIO_VOLUME_UP_L";
		};
		gpio_ec_voldn_btn_odl: ec_voldn_btn_odl {
			gpios = <&gpioe 2 GPIO_INPUT>;
			enum-name = "GPIO_VOLUME_DOWN_L";
		};
		gpio_ccd_mode_odl: ccd_mode_odl {
			gpios = <&gpioe 5 GPIO_INPUT>;
			enum-name = "GPIO_CCD_MODE_ODL";
		};

		/* unimplemented GPIOs */
		entering-rw {
			enum-name = "GPIO_ENTERING_RW";
		};
	};

	/*
	 * aliases for sub-board GPIOs
	 */
	aliases {
		gpio-en-hdmi-pwr = &gpio_ec_x_gpio1;
		gpio-usb-c1-frs-en = &gpio_ec_x_gpio1;
		gpio-usb-c1-ppc-int-odl = &gpio_x_ec_gpio2;
		gpio-ps185-ec-dp-hpd = &gpio_x_ec_gpio2;
		gpio-usb-c1-dp-in-hpd = &gpio_ec_x_gpio3;
		gpio-ps185-pwrdn-odl = &gpio_ec_x_gpio3;
	};

	hibernate-wake-pins {
		compatible = "cros-ec,hibernate-wake-pins";
		wakeup-irqs = <
			&int_ac_present
			&int_power_button
			&int_lid_open
		>;
	};

	unused-pins {
		compatible = "unused-gpios";
		unused-gpios =
			/* base_imu_int_l: base_imu_int_l */
			<&gpio5 6 0>,
			/* ec_pen_chg_dis_odl */
			<&gpioe 4 0>,
			/* gpio_tablet_mode_l: tablet_mode_l */
			<&gpiob 2 0>,
			/* lid_accel_int_l */
			<&gpiob 3 0>,
			/* LED3 */
			<&gpioc 4 0>;
	};
};
```

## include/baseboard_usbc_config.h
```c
/* Copyright 2021 The ChromiumOS Authors
 * Use of this source code is governed by a BSD-style license that can be
 * found in the LICENSE file.
 */

/* Corsola daughter board detection */

#ifndef __CROS_EC_BASEBOARD_USBC_CONFIG_H
#define __CROS_EC_BASEBOARD_USBC_CONFIG_H

#include "gpio.h"

#include <zephyr/sys/util_macro.h>

#ifdef CONFIG_PLATFORM_EC_USB_PD_TCPM_RT1718S
#define GPIO_EN_USB_C1_SINK RT1718S_GPIO1
#define GPIO_EN_USB_C1_SOURCE RT1718S_GPIO2
#define GPIO_EN_USB_C1_FRS RT1718S_GPIO3
#endif

void ppc_interrupt(enum gpio_signal signal);
void ccd_interrupt(enum gpio_signal signal);
void hdmi_hpd_interrupt(enum gpio_signal signal);
void ps185_hdmi_hpd_mux_set(void);
int corsola_is_dp_muxable(int port);
int ps8743_eq_c1_setting(const struct usb_mux *me);

/* USB-A ports */
enum usba_port { USBA_PORT_A0 = 0, USBA_PORT_COUNT };

/* USB-C ports */
#define USBC_PORT_N(i, _) USBC_PORT_C##i = i
enum usbc_port {
	LISTIFY(CONFIG_USB_PD_PORT_MAX_COUNT, USBC_PORT_N, (, )),
	USBC_PORT_COUNT
};

/**
 * Is the port fine to be muxed its DisplayPort lines?
 *
 * Only one port can be muxed to DisplayPort at a time.
 *
 * @param port	Port number of TCPC.
 * @return	1 is fine; 0 is bad as other port is already muxed;
 */
int corsola_is_dp_muxable(int port);

#endif /* __CROS_EC_BASEBOARD_USBC_CONFIG_H */
```

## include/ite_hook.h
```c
/* Copyright 2025 The ChromiumOS Authors
 * Use of this source code is governed by a BSD-style license that can be
 * found in the LICENSE file.
 */

/* Corsola Hook function  */

#ifndef __CROS_EC_ITEHOOK_H
#define __CROS_EC_ITEHOOK_H

#include <stdint.h>

__override_proto void board_rt9490_enable_adc(void)

#endif /* __CROS_EC_ITEHOOK_H */
```

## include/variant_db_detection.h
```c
/* Copyright 2021 The ChromiumOS Authors
 * Use of this source code is governed by a BSD-style license that can be
 * found in the LICENSE file.
 */

/* Corsola daughter board detection */

#ifndef __CROS_EC_CORSOLA_DB_DETECTION_H
#define __CROS_EC_CORSOLA_DB_DETECTION_H

#include <stdint.h>

enum corsola_db_type {
	CORSOLA_DB_UNINIT = -1,
	/* CORSOLA_DB_NO_DETECTION means there is no detection involved in. */
	CORSOLA_DB_NO_DETECTION,
	/* CORSOLA_DB_NONE means there is no DB in the design. */
	CORSOLA_DB_NONE,
	CORSOLA_DB_TYPEC,
	CORSOLA_DB_HDMI,
	CORSOLA_DB_COUNT,
};

/*
 * Get the connected daughterboard type.
 *
 * @return		The daughterboard type.
 */
enum corsola_db_type corsola_get_db_type(void);
#if !defined(CONFIG_VARIANT_CORSOLA_DB_DETECTION) && !defined(CONFIG_TEST)
inline enum corsola_db_type corsola_get_db_type(void)
{
	return CORSOLA_DB_NO_DETECTION;
}
#endif

/* return the adjusted port count for board overridden usbc/charger functions.
 */
test_mockable uint8_t board_get_adjusted_usb_pd_port_count(void);

#endif /* __CROS_EC_CORSOLA_DB_DETECTION_H */
```

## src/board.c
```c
<<<<<<< HEAD   (c8af73 Revert "Merge remote-tracking branch cros/main into factory-)
=======
/* Copyright 2022 The ChromiumOS Authors
 * Use of this source code is governed by a BSD-style license that can be
 * found in the LICENSE file.
 */

#include "baseboard_usbc_config.h"
#include "console.h"
#include "hooks.h"
#include "typec_control.h"

#define CPRINTS(format, args...) cprints(CC_USB, format, ##args)

static void ccd_interrupt_deferred(void)
{
	/*
	 * If CCD_MODE_ODL asserts, it means there's a debug accessory connected
	 * and we should enable the SBU FETs.
	 */
	typec_set_sbu(CONFIG_CCD_USBC_PORT_NUMBER, 1);

	/* Mux DP AUX away when CCD enabled to prevent the AUX channel
	 * interferes the SBU pins.
	 */
	CPRINTS("CCD Enabled, mux DP_AUX_PATH_SEL to 1");
	gpio_pin_set_dt(GPIO_DT_FROM_NODELABEL(dp_aux_path_sel), 1);
}
DECLARE_DEFERRED(ccd_interrupt_deferred);

void ccd_interrupt(enum gpio_signal signal)
{
	hook_call_deferred(&ccd_interrupt_deferred_data, 0);
}
>>>>>>> BRANCH (2c3025 PCHG: Print next event in pchg console command)
```

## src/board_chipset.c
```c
/* Copyright 2021 The ChromiumOS Authors
 * Use of this source code is governed by a BSD-style license that can be
 * found in the LICENSE file.
 */

/* Corsola baseboard-chipset specific configuration */

#include "gpio_signal.h"

#include <zephyr/drivers/gpio.h>
#include <zephyr/init.h>

#include <ap_power/ap_power.h>

static void board_backlight_handler(struct ap_power_ev_callback *cb,
				    struct ap_power_ev_data data)
{
	int value;

	switch (data.event) {
	default:
		return;

	case AP_POWER_RESUME:
		/* Called on AP S3 -> S0 transition */
		value = 1;
		break;

	case AP_POWER_SUSPEND:
		/* Called on AP S0 -> S3 transition */
		value = 0;
		break;
	}
	k_busy_wait(50 * USEC_PER_MSEC);
	gpio_pin_set_dt(GPIO_DT_FROM_NODELABEL(gpio_ec_bl_en_od), value);
}

static int install_backlight_handler(void)
{
	static struct ap_power_ev_callback cb;

	/*
	 * Add a callback for suspend/resume to
	 * control the keyboard backlight.
	 */
	ap_power_ev_init_callback(&cb, board_backlight_handler,
				  AP_POWER_RESUME | AP_POWER_SUSPEND);
	ap_power_ev_add_callback(&cb);
	return 0;
}

SYS_INIT(install_backlight_handler, APPLICATION, 1);
```

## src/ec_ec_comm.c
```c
/* Copyright 2022 The Chromium OS Authors. All rights reserved.
 * Use of this source code is governed by a BSD-style license that can be
 * found in the LICENSE file.
 */

#include <zephyr/drivers/uart.h>
#include <zephyr/devicetree.h>
#include <zephyr/kernel.h>

#include "chip_chipregs.h"
#include "crc8.h"
#include "cros_board_info.h"
#include "hooks.h"
#include "console.h"
#include "lid_switch.h"
#include "queue.h"
#include "host_command.h"
#include "keyboard_mkbp.h"
#include "touchpad.h"
#include "usb_hid_touchpad.h"

#define HEADER_SIZE 5
#define PACKET_SIZE 3

static const struct device* uart = DEVICE_DT_GET(DT_NODELABEL(uart2));
static enum {
	MODE_UNKNOWN = 0,
	MODE_BASE,
	MODE_LID
} mode;

static struct queue tx_queue = QUEUE_NULL(512, uint8_t);
static struct queue rx_queue = QUEUE_NULL(512, uint8_t);

void board_uart_tx(const uint8_t* data, int size)
{
	uint8_t header[HEADER_SIZE] = {55, 66, size, 0 /* crc */, mode /* sender */};

	if (size >= 256) {
		return;
	}

	header[3] = cros_crc8(data, size);

	queue_add_units(&tx_queue, header, sizeof(header));
	queue_add_units(&tx_queue, data, size);

	uart_irq_tx_enable(uart);
}

void send_stop(void)
{
	static uint8_t zeros[64] = {};
	queue_add_units(&tx_queue, zeros, sizeof(zeros));
}

void process_packet(const uint8_t *header, uint8_t *data)
{
	if (header[4] == mode) {
		return;
	}

	if (cros_crc8(data, PACKET_SIZE) != header[3]) {
		return;
	}

#ifdef CONFIG_KEYBOARD_PROTOCOL_MKBP
	if (mode == MODE_LID) {
		int row = data[0], col = data[1], pressed = data[2];
		static uint8_t state[KEYBOARD_COLS_MAX] = {};

		if (pressed) {
			state[col] |= BIT(row);
		} else {
			state[col] &= ~BIT(row);
		}
		mkbp_keyboard_add(state);
		ccprintf("keyboard event: %d %d %d\n", row, col, pressed);
	}
#endif
	if (mode == MODE_BASE) {
		ccprintf("control command received %02x %02x\n", data[0], data[1]);
	}
}

void uart_handler(const struct device *dev, void *user_data)
{
	static int zero_count = 0;

	uart_irq_update(dev);

	if (queue_is_empty(&tx_queue)) {
		uart_irq_tx_disable(dev);
	} else if (uart_irq_tx_ready(dev)) {
		struct queue_chunk chunk = queue_get_read_chunk(&tx_queue);
		int bytes_sent = uart_fifo_fill(uart, chunk.buffer, chunk.count);

		if (bytes_sent > 0) {
			queue_advance_head(&tx_queue, bytes_sent);
			uart_irq_tx_enable(uart);
		}
	} else if (!uart_irq_tx_ready(dev)) {
		uart_irq_tx_enable(dev);
	}

	if (uart_irq_rx_ready(dev)) {
		while (true) {
			uint8_t buf[32];
			int bytes_read = uart_fifo_read(uart, buf, sizeof(buf));

			if (bytes_read > 0) {
				queue_add_units(&rx_queue, buf, bytes_read);
			} else {
				break;
			}
		}

		while (queue_count(&rx_queue) >= HEADER_SIZE + PACKET_SIZE) {
			uint8_t header[HEADER_SIZE] = {}, data[PACKET_SIZE];

			queue_peek_units(&rx_queue, &header, 0, sizeof(header));

			if (header[0] == 0) {
				++zero_count;
			} else {
				zero_count = 0;
			}
			if (mode == MODE_BASE && zero_count == 16) {
				ccprintf("\x1b[1;31mstop tx\x1b[m\n");
			}

			if (header[0] != 55 || header[1] != 66 || header[2] != PACKET_SIZE) {
				queue_advance_head(&rx_queue, 1);
				continue;
			}

			queue_advance_head(&rx_queue, sizeof(header));
			queue_remove_units(&rx_queue, data, sizeof(data));

			process_packet(header, data);
		}
	}
}

void force_lid_open(void)
{
	enable_lid_detect(false);
}
DECLARE_HOOK(HOOK_INIT, force_lid_open, HOOK_PRIO_INIT_LID + 1);

static int ec_ec_comm_init(const struct device *unused)
{
	char oem_name[10];
	uint8_t out_size = sizeof(oem_name);

	/* UART1PMR */
	ECREG(IT83XX_SPI_BASE + 0x23) = 1;

	cbi_get_board_info(CBI_TAG_OEM_NAME, oem_name, &out_size);
	if (strncmp(oem_name, "base", 4) == 0) {
		ccprintf("\x1b[1;31mmode = BASE\x1b[m");
		mode = MODE_BASE;
	} else if (strncmp(oem_name, "lid", 3) == 0) {
		ccprintf("\x1b[1;31mmode = LID\x1b[m");
		mode = MODE_LID;
	} else {
		mode = MODE_UNKNOWN;
	}

	uart_irq_callback_user_data_set(uart, uart_handler, NULL);
	uart_irq_rx_enable(uart);

	return 0;
}
SYS_INIT(ec_ec_comm_init, APPLICATION, 1);

static int command_ctrl(int argc, const char **argv)
{
	uint8_t msg[3] = {0x77, 0x88, 0x99};

	send_stop();
	board_uart_tx(msg, sizeof(msg));
	return 0;
}
DECLARE_CONSOLE_COMMAND(ctrl, command_ctrl, "", "");

#ifndef CONFIG_KEYBOARD_PROTOCOL_MKBP
void keyboard_state_changed(int row, int col, int is_pressed)
{
	uint8_t msg[3] = {row, col, is_pressed};

	ccprintf("keyboard event: %d %d %d\n", row, col, is_pressed);
	if (mode == MODE_LID) {
		return;
	}
	board_uart_tx(msg, sizeof(msg));
}

void keyboard_clear_buffer(void)
{
	/* release all keys? */
}

void clear_typematic_key(void)
{
}
#endif

#ifdef CONFIG_TOUCHPAD
void board_touchpad_reset(void)
{
}

void set_touchpad_report(struct usb_hid_touchpad_report *report)
{
	ccprintf("touchpad report\n");
}
#endif
```

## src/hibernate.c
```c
/* Copyright 2021 The ChromiumOS Authors
 * Use of this source code is governed by a BSD-style license that can be
 * found in the LICENSE file.
 */
#include "charger.h"
#include "driver/charger/isl923x_public.h"
#include "system.h"

#include <zephyr/drivers/gpio.h>

/* Corsola board specific hibernate implementation */
__override void board_hibernate(void)
{
#ifdef CONFIG_CHARGER_ISL9238C
	isl9238c_hibernate(CHARGER_SOLO);
#endif
}

__override void board_hibernate_late(void)
{
#ifdef CONFIG_CORSOLA_HIBERNATE_PRE_OFF_5V
	/*
	 * b:283037861
	 * This CONFIG_CORSOLA_HIBERNATE_PRE_OFF_5V will
	 * change hibernate behavior. Specifically, it will
	 * disable pp5000_z2 power line and a short delay,
	 * then perform the common corsola hibernate.
	 */
	gpio_pin_set_dt(GPIO_DT_FROM_NODELABEL(en_pp5000_z2), 1);
	/* It takes around 30ms to release the PP5000 capacitance. */
	udelay(30 * MSEC);
#endif
	gpio_pin_set_dt(GPIO_DT_FROM_NODELABEL(gpio_en_ulp), 1);
}
```

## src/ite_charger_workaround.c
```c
/* Copyright 2022 The ChromiumOS Authors
 * Use of this source code is governed by a BSD-style license that can be
 * found in the LICENSE file.
 */

#include "charger.h"
#include "driver/charger/rt9490.h"
#include "hooks.h"
#include "i2c.h"
#include "system.h"

#include <zephyr/sys/util.h>

/*
 * This workaround and the board id checks only apply to krabby and early
 * tentacruel devices.
 * Newer project should have all of these fixed.
 */
BUILD_ASSERT(IS_ENABLED(CONFIG_BOARD_KRABBY) || 
	     IS_ENABLED(CONFIG_BOARD_TENTACRUEL) ||IS_ENABLED(CONFIG_TEST));

/* b/194967754#comment5: work around for IBUS ADC unstable issue */
static void ibus_adc_workaround(void)
{
	if (system_get_board_version() != 0) {
		return;
	}

	i2c_update8(chg_chips[CHARGER_SOLO].i2c_port,
		    chg_chips[CHARGER_SOLO].i2c_addr_flags,
		    RT9490_REG_ADC_CHANNEL0, RT9490_VSYS_ADC_DIS, MASK_SET);

	rt9490_enable_hidden_mode(CHARGER_SOLO, true);
	/* undocumented registers... */
	i2c_write8(chg_chips[CHARGER_SOLO].i2c_port,
		   chg_chips[CHARGER_SOLO].i2c_addr_flags, 0x52, 0xC4);

	i2c_update8(chg_chips[CHARGER_SOLO].i2c_port,
		    chg_chips[CHARGER_SOLO].i2c_addr_flags,
		    RT9490_REG_ADC_CHANNEL0, RT9490_VSYS_ADC_DIS, MASK_CLR);
	rt9490_enable_hidden_mode(CHARGER_SOLO, false);
}

/* b/214880220#comment44: lock i2c at 400khz */
static void i2c_speed_workaround(void)
{
	if (system_get_board_version() >= 3) {
		return;
	}

	rt9490_enable_hidden_mode(CHARGER_SOLO, true);
	/* Set to Auto mode, default run at 400kHz */
	i2c_write8(chg_chips[CHARGER_SOLO].i2c_port,
		   chg_chips[CHARGER_SOLO].i2c_addr_flags, 0x71, 0x22);
	/* Manually select for 400kHz, valid only when 0x71[7] == 1 */
	i2c_write8(chg_chips[CHARGER_SOLO].i2c_port,
		   chg_chips[CHARGER_SOLO].i2c_addr_flags, 0xF7, 0x14);
	rt9490_enable_hidden_mode(CHARGER_SOLO, false);
}

static void eoc_deglitch_workaround(void)
{
	if (system_get_board_version() != 1) {
		return;
	}

	/* set end-of-charge deglitch time to 2ms */
	i2c_update8(chg_chips[CHARGER_SOLO].i2c_port,
		    chg_chips[CHARGER_SOLO].i2c_addr_flags,
		    RT9490_REG_ADD_CTRL0, RT9490_TD_EOC, MASK_CLR);
}

static void disable_safety_timer(void)
{
	if (system_get_board_version() >= 2) {
		return;
	}
	/* Disable charge timer */
	i2c_write8(chg_chips[CHARGER_SOLO].i2c_port,
		   chg_chips[CHARGER_SOLO].i2c_addr_flags,
		   RT9490_REG_SAFETY_TMR_CTRL,
		   RT9490_EN_TRICHG_TMR | RT9490_EN_PRECHG_TMR |
			   RT9490_EN_FASTCHG_TMR);
}

static void board_rt9490_workaround(void)
{
	ibus_adc_workaround();
	i2c_speed_workaround();
	eoc_deglitch_workaround();
	disable_safety_timer();
}
DECLARE_HOOK(HOOK_INIT, board_rt9490_workaround, HOOK_PRIO_DEFAULT);
```

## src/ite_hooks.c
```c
/* Copyright 2021 The ChromiumOS Authors
 * Use of this source code is governed by a BSD-style license that can be
 * found in the LICENSE file.
 */

#include "charger.h"
#include "driver/charger/rt9490.h"
#include "extpower.h"
#include "hooks.h"

#include <zephyr/drivers/gpio.h>
#include <zephyr/drivers/pinctrl.h>
#include <zephyr/init.h>

#include <ap_power/ap_power.h>

#define I2C3_NODE DT_NODELABEL(i2c3)
PINCTRL_DT_DEFINE(I2C3_NODE);

static void board_i2c3_ctrl(bool enable)
{
	if (DEVICE_DT_GET(
		    DT_GPIO_CTLR_BY_IDX(DT_NODELABEL(i2c3), scl_gpios, 0)) ==
	    DEVICE_DT_GET(DT_NODELABEL(gpiof))) {
		const struct pinctrl_dev_config *pcfg =
			PINCTRL_DT_DEV_CONFIG_GET(I2C3_NODE);

		if (enable) {
			pinctrl_apply_state(pcfg, PINCTRL_STATE_DEFAULT);
		} else {
			pinctrl_apply_state(pcfg, PINCTRL_STATE_SLEEP);
		}
	}
}

static void board_enable_i2c3(void)
{
	board_i2c3_ctrl(1);
}
DECLARE_HOOK(HOOK_CHIPSET_PRE_INIT, board_enable_i2c3, HOOK_PRIO_FIRST);

static void board_disable_i2c3(void)
{
	board_i2c3_ctrl(0);
}
DECLARE_HOOK(HOOK_CHIPSET_HARD_OFF, board_disable_i2c3, HOOK_PRIO_LAST);

static void board_suspend_handler(struct ap_power_ev_callback *cb,
				  struct ap_power_ev_data data)
{
	int value;

	switch (data.event) {
	default:
		return;

	case AP_POWER_RESUME:
		value = 1;
		break;

	case AP_POWER_SUSPEND:
		value = 0;
		break;
	}
	gpio_pin_set_dt(GPIO_DT_FROM_NODELABEL(gpio_en_5v_usm), value);
}

static int install_suspend_handler(void)
{
	static struct ap_power_ev_callback cb;

	/*
	 * Add a callback for suspend/resume.
	 */
	ap_power_ev_init_callback(&cb, board_suspend_handler,
				  AP_POWER_RESUME | AP_POWER_SUSPEND);
	ap_power_ev_add_callback(&cb);
	return 0;
}

SYS_INIT(install_suspend_handler, APPLICATION, 1);

__overridable void board_rt9490_enable_adc(void)
{
	if (system_get_board_version() >= 1) {
		rt9490_enable_adc(CHARGER_SOLO, extpower_is_present());
	}
}

static void board_hook_ac_change(void)
{
	board_rt9490_enable_adc();
}
DECLARE_HOOK(HOOK_AC_CHANGE, board_hook_ac_change, HOOK_PRIO_DEFAULT);
DECLARE_HOOK(HOOK_INIT, board_hook_ac_change, HOOK_PRIO_LAST);
```

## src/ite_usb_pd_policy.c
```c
/* Copyright 2021 The ChromiumOS Authors
 * Use of this source code is governed by a BSD-style license that can be
 * found in the LICENSE file.
 */

#include "adc.h"
#include "charge_manager.h"
#include "usb_charge.h"
#include "usb_pd.h"
#include "usbc_ppc.h"

int pd_snk_is_vbus_provided(int port)
{
#ifdef CONFIG_USB_CHARGER
	static atomic_t vbus_prev[CONFIG_USB_PD_PORT_MAX_COUNT];
#endif
	int vbus;

	/*
	 * (b:181203590#comment20) TODO(yllin): use
	 *  PD_VSINK_DISCONNECT_PD for non-5V case.
	 */
	vbus = adc_read_channel(board_get_vbus_adc(port)) >=
	       PD_V_SINK_DISCONNECT_MAX;

#ifdef CONFIG_USB_CHARGER
	/*
	 * There's no PPC to inform VBUS change for usb_charger, so inform
	 * the usb_charger now.
	 */
	if (!!(vbus_prev[port] != vbus)) {
		usb_charger_vbus_change(port, vbus);
	}

	if (vbus) {
		atomic_or(&vbus_prev[port], 1);
	} else {
		atomic_clear(&vbus_prev[port]);
	}
#endif
	return vbus;
}

int board_vbus_source_enabled(int port)
{
	return ppc_is_sourcing_vbus(port);
}
```
